# PTM160xx register map
File version: 0.2
Registers are 32-bit, read-write, reset 0x0 unless marked. A register's access mark holds for its fields unless they carry their own. Offsets are from the block's base; [hi:lo] are bit positions; {n}, {i} and the like mark numbered series.

## CMP0
Base 0x40000800
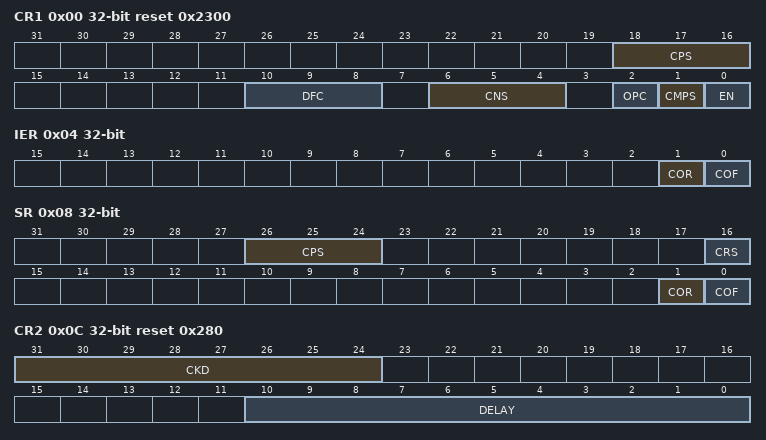
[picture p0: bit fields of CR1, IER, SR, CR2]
0x00 CR1 reset 0x2300 — Control Register 1
  [18:16] CPS — Comparator positive intput selection
  [10:8] DFC — Digital filter configuration
  [6:4] CNS — Comparator negative intput selection
  [2] OPC — Comparator output polarity control
  [1] CMPS — Comparator power mode selection
  [0] EN — Comparator enable
0x04 IER — Interrupt Enable Register
  [1] COR — Comparator output rising edge interrupt enable
  [0] COF — Comparator output falling edge interrupt enable
0x08 SR access per field — Status Register
  [26:24] CPS ro — Current comparator positive intput
  [16] CRS ro — Comparator result
  [1] COR rw — Comparator output rising edge flag
  [0] COF rw — Comparator output falling edge flag
0x0C CR2 reset 0x280 — Control Register 2
  [31:24] CKD — Sampling clock division
  [10:0] DELAY — Comparator Initialization delay time
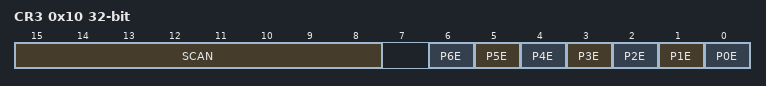
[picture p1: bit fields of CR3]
0x10 CR3 — Control Register 3
  [15:8] SCAN — Comparator positive intput Scan Time
  [n] P{n}E (n=0..6) — Comparator {n} positive intput y scan enable

## OPA0
Base 0x40015C00
Same registers: OPA1 0x40015D00
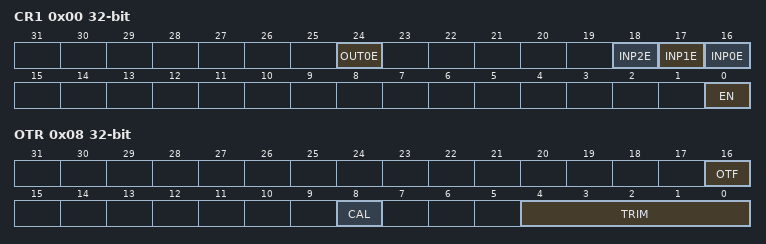
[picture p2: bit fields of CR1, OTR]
0x00 CR1 — Control Register 1
  [24] OUT0E — OPA output 0 enable
  [18] INP2E — OPA positiveintput 2 enable
  [17] INP1E — OPA positiveintput 1 enable
  [16] INP0E — OPA positiveintput 0 enable
  [0] EN — OPA enable
0x08 OTR access per field — Offset Trimming Register
  [16] OTF ro — Offset trimming value source flag
  [8] CAL ro — OPA calibration output
  [4:0] TRIM rw — Offset trimming value

## LDAC
Base 0x40014000
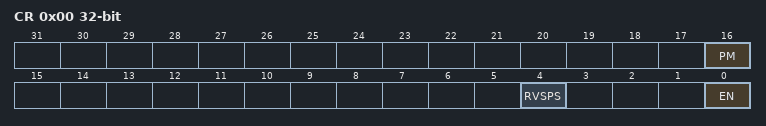
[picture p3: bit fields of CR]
0x00 CR — Control Register
  [16] PM — Power mode
  [4] RVSPS — Reference voltage source positive selection
  [0] EN — LDAC enable
0x04 DR — Data Register
  [4:0] DATA — LDAC data

## PWM — PWM Controller
Base 0x4000F800
0x00 CR1 — Control Register 1
  [0] EN — PWM enable
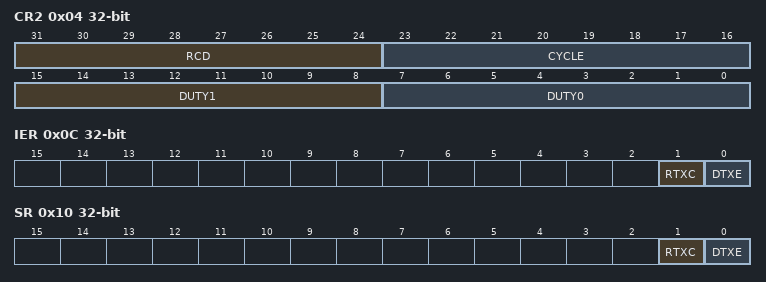
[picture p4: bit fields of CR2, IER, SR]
0x04 CR2 — Control Register 2
  [31:24] RCD — Reset code duration
  [23:16] CYCLE — PWM cycle
  [15:8] DUTY1 — code 1 positive duty
  [7:0] DUTY0 — code 0 positive duty
0x08 DR — Data Register
  [23:0] DATA — code data
0x0C IER — Interrupt Enable Register
  [1] RTXC — Reset code Transmit completed interrupt enable
  [0] DTXE — Data code Transmit empty interrupt enable
0x10 SR — Status Register
  [1] RTXC — Reset code Transmit completed flag
  [0] DTXE — Data code Transmit empty flag

## IFMC — On-chip flash memory controller
Base 0x40000000
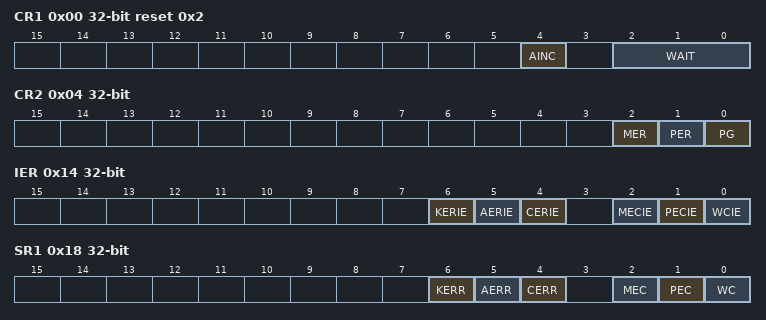
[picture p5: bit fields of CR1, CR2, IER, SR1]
0x00 CR1 reset 0x2 — Control Register 1
  [4] AINC — Address auto increment control
  [2:0] WAIT — instruction fetch wait cycle
0x04 CR2 wo — Control Register 2
  [2] MER — Mass erase
  [1] PER — Pageerase
  [0] PG — Programming
0x0C KR1 access per field — Key Register 1
  [31:16] UKEY wo — Register unlock key
  [16] LOCK ro — Register lock status
  [15:0] KEY wo — IFMC key
  [2:0] AREA ro — IFMC operation area
0x10 KR2 access per field — Key Register 2
  [31:16] UKEY wo — Register unlock key
  [16] LOCK2 ro — Register lock status 2
  [15:0] KEY wo — IFMC key
  [0] LOCK1 ro — Register lock status 1
0x14 IER — Interrupt Enable Register
  [6] KERIE — Key error interrupt enable
  [5] AERIE — Address error interrupt enable
  [4] CERIE — Operation command error interrupt enable
  [2] MECIE — Mass erase operation complete interrupt enable
  [1] PECIE — Page erase operation complete interrupt enable
  [0] WCIE — Write operation complete interrupt enable
0x18 SR1 — Status Register 1
  [6] KERR — Key error
  [5] AERR — Address error
  [4] CERR — Operation command error
  [2] MEC — Mass erase operation complete
  [1] PEC — Page erase operation complete
  [0] WC — Write operation complete
0x20 AR reset 0xFFFFFFFF — Address Register
  [31:0] AR — IFMC words addr
0x24 DR1 — Data Register 1
  [31:0] DR — IFMC data
0x30 OPTCR access per field reset 0xAA — Option Control Register
  [7:0] RDP rw — Read protect
  [31:0] KEY wo — Key value

## ES — Device Electronic Signature
Base 0x40020800
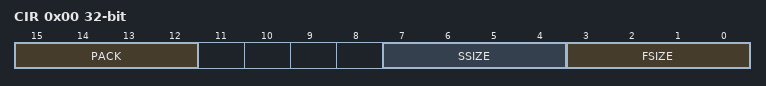
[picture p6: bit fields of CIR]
0x00 CIR ro — Chip Information Register
  [15:12] PACK — Package
  [7:4] SSIZE — Size of sram memory
  [3:0] FSIZE — Size of flash memory
0x0C CIDR1 ro reset 0xFFFFFFFF — Chip ID Register 1
  [31:0] CID — Chip ID
0x10 CIDR2 ro — Chip ID Register 2
  [31:0] CID — Chip ID
0x14 CIDR3 ro — Chip ID Register 3
  [31:0] CID — Chip ID
0x18 UDIR1 reset 0xFFFFFFFF — User-Defined Information Register 1
  [31:0] INFO — User-defined information
0x1C UDIR2 reset 0xFFFFFFFF — User-Defined Information Register 2
  [31:0] INFO — User-defined information
